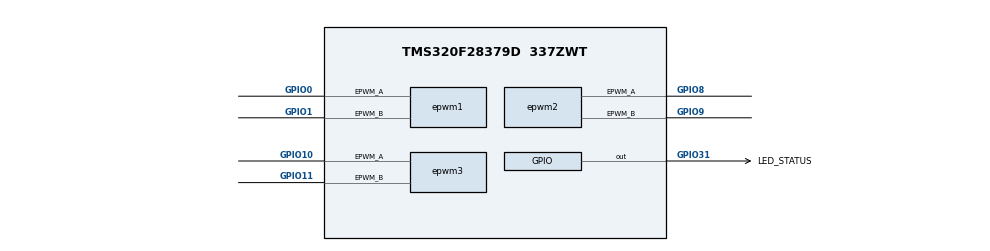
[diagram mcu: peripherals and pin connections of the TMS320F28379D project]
/**
 * These arguments were used when this file was generated. They will be automatically applied on subsequent loads
 * via the GUI or CLI. Run CLI with '--help' for additional information on how to override these arguments.
 * @cliArgs --device "F2837xD" --part "F2837xD_337ZWT" --package "F2837xD_337ZWT" --context "CPU1" --product "C2000WARE@26.00.00.00"
 * @v2CliArgs --device "TMS320F28379D" --package "337ZWT" --context "CPU1" --product "C2000WARE@26.00.00.00"
 * @versions {"tool":"1.27.1+4634"}
 */

/**
 * Import the modules used in this configuration.
 */
const adc   = scripting.addModule("/driverlib/adc.js", {}, false);
const adc1  = adc.addInstance();
const adc2  = adc.addInstance();
const led   = scripting.addModule("/driverlib/board_components/led", {}, false);
const led1  = led.addInstance();
const epwm  = scripting.addModule("/driverlib/epwm.js", {}, false);
const epwm1 = epwm.addInstance();
const epwm2 = epwm.addInstance();
const epwm3 = epwm.addInstance();

/**
 * Write custom configuration values to the imported modules.
 */
adc1.adcClockPrescaler       = "ADC_CLK_DIV_4_0";
adc1.enabledSOCs             = ["ADC_SOC_NUMBER0","ADC_SOC_NUMBER2","ADC_SOC_NUMBER3"];
adc1.enabledInts             = ["ADC_INT_NUMBER1"];
adc1.interruptPulseMode      = "ADC_PULSE_END_OF_CONV";
adc1.registerInterrupts      = ["1"];
adc1.soc0Trigger             = "ADC_TRIGGER_EPWM1_SOCA";
adc1.soc0SampleWindow        = 15;
adc1.soc2Channel             = "ADC_CH_ADCIN1";
adc1.soc2Trigger             = "ADC_TRIGGER_EPWM1_SOCA";
adc1.soc2SampleWindow        = 15;
adc1.soc3Channel             = "ADC_CH_ADCIN2";
adc1.soc3Trigger             = "ADC_TRIGGER_EPWM1_SOCA";
adc1.soc3SampleWindow        = 15;
adc1.enableInterrupt1        = true;
adc1.interrupt1SOCSource     = "ADC_SOC_NUMBER3";
adc1.$name                   = "myADCA";
adc1.adcInt1.enableInterrupt = true;

adc2.adcBase           = "ADCB_BASE";
adc2.adcClockPrescaler = "ADC_CLK_DIV_4_0";
adc2.enabledSOCs       = ["ADC_SOC_NUMBER1"];
adc2.soc1Channel       = "ADC_CH_ADCIN1";
adc2.soc1Trigger       = "ADC_TRIGGER_EPWM1_SOCA";
adc2.soc1SampleWindow  = 15;
adc2.$name             = "myADCB";

led1.$name                = "LED_STATUS";
led1.gpio.gpioPin.$assign = "GPIO31";

epwm1.epwmEventTrigger_EPWM_SOC_A_triggerEnable                  = true;
epwm1.$name                                                      = "PWM_W";
epwm1.epwmTimebase_counterMode                                   = "EPWM_COUNTER_MODE_UP_DOWN";
epwm1.epwmTimebase_period                                        = 5000;
epwm1.epwmTimebase_syncOutPulseMode                              = "EPWM_SYNC_OUT_PULSE_ON_COUNTER_ZERO";
epwm1.epwmCounterCompare_cmpA                                    = 2500;
epwm1.epwmActionQualifier_EPWM_AQ_OUTPUT_A_ON_TIMEBASE_UP_CMPA   = "EPWM_AQ_OUTPUT_HIGH";
epwm1.epwmActionQualifier_EPWM_AQ_OUTPUT_A_ON_TIMEBASE_DOWN_CMPA = "EPWM_AQ_OUTPUT_LOW";
epwm1.epwmDeadband_enableRED                                     = true;
epwm1.epwmDeadband_enableFED                                     = true;
epwm1.epwmDeadband_delayRED                                      = 50;
epwm1.epwmDeadband_delayFED                                      = 50;
epwm1.epwmDeadband_polarityFED                                   = "EPWM_DB_POLARITY_ACTIVE_LOW";
epwm1.epwmEventTrigger_EPWM_SOC_A_triggerSource                  = "EPWM_SOC_TBCTR_ZERO";
epwm1.epwmEventTrigger_EPWM_SOC_A_triggerEventPrescalar          = "1";
epwm1.epwm.$assign                                               = "EPWM1";
epwm1.epwm.epwm_aPin.$assign                                     = "GPIO0";
epwm1.epwm.epwm_bPin.$assign                                     = "GPIO1";

epwm2.$name                                                      = "PWM_V";
epwm2.epwmTimebase_counterMode                                   = "EPWM_COUNTER_MODE_UP_DOWN";
epwm2.epwmTimebase_period                                        = 5000;
epwm2.epwmTimebase_syncOutPulseMode                              = "EPWM_SYNC_OUT_PULSE_ON_EPWMxSYNCIN";
epwm2.epwmTimebase_phaseEnable                                   = true;
epwm2.epwmCounterCompare_cmpA                                    = 2500;
epwm2.epwmActionQualifier_EPWM_AQ_OUTPUT_A_ON_TIMEBASE_UP_CMPA   = "EPWM_AQ_OUTPUT_HIGH";
epwm2.epwmActionQualifier_EPWM_AQ_OUTPUT_A_ON_TIMEBASE_DOWN_CMPA = "EPWM_AQ_OUTPUT_LOW";
epwm2.epwmDeadband_enableRED                                     = true;
epwm2.epwmDeadband_enableFED                                     = true;
epwm2.epwmDeadband_delayRED                                      = 50;
epwm2.epwmDeadband_delayFED                                      = 50;
epwm2.epwmDeadband_polarityFED                                   = "EPWM_DB_POLARITY_ACTIVE_LOW";
epwm2.epwmTimebase_counterModeAfterSync                          = "EPWM_COUNT_MODE_UP_AFTER_SYNC";
epwm2.epwm.$assign                                               = "EPWM5";
epwm2.epwm.epwm_aPin.$assign                                     = "GPIO8";
epwm2.epwm.epwm_bPin.$assign                                     = "GPIO9";

epwm3.$name                                                      = "PWM_U";
epwm3.epwmTimebase_counterMode                                   = "EPWM_COUNTER_MODE_UP_DOWN";
epwm3.epwmTimebase_period                                        = 5000;
epwm3.epwmTimebase_syncOutPulseMode                              = "EPWM_SYNC_OUT_PULSE_ON_EPWMxSYNCIN";
epwm3.epwmTimebase_phaseEnable                                   = true;
epwm3.epwmCounterCompare_cmpA                                    = 2500;
epwm3.epwmActionQualifier_EPWM_AQ_OUTPUT_A_ON_TIMEBASE_UP_CMPA   = "EPWM_AQ_OUTPUT_HIGH";
epwm3.epwmActionQualifier_EPWM_AQ_OUTPUT_A_ON_TIMEBASE_DOWN_CMPA = "EPWM_AQ_OUTPUT_LOW";
epwm3.epwmDeadband_enableRED                                     = true;
epwm3.epwmDeadband_enableFED                                     = true;
epwm3.epwmDeadband_delayRED                                      = 50;
epwm3.epwmDeadband_delayFED                                      = 50;
epwm3.epwmDeadband_polarityFED                                   = "EPWM_DB_POLARITY_ACTIVE_LOW";
epwm3.epwmTimebase_counterModeAfterSync                          = "EPWM_COUNT_MODE_UP_AFTER_SYNC";
epwm3.epwm.$assign                                               = "EPWM6";
epwm3.epwm.epwm_aPin.$assign                                     = "GPIO10";
epwm3.epwm.epwm_bPin.$assign                                     = "GPIO11";
